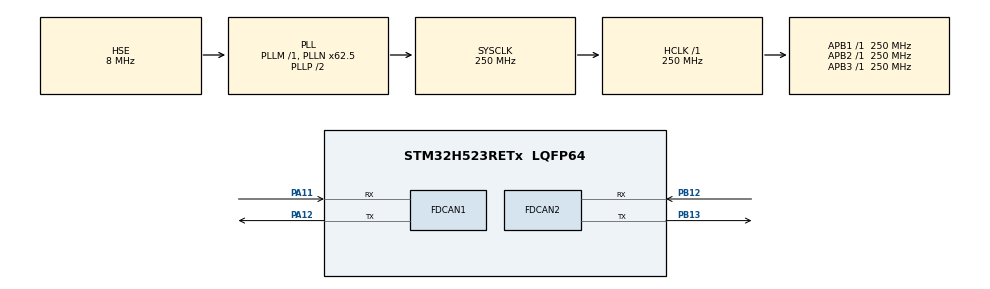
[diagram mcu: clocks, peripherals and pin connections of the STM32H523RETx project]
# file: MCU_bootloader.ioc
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BOOTPATH.BootPathName=LEGACY
BOOTPATH.UserSelectedBootPath=LEGACY
CORTEX_M33_NS.userName=CORTEX_M33
FDCAN1.CalculateBaudRateNominal=250000
FDCAN1.CalculateTimeBitNominal=4000
FDCAN1.CalculateTimeQuantumNominal=1000.0
FDCAN1.DataTimeSeg1=21
FDCAN1.ExtFiltersNbr=1
FDCAN1.NominalPrescaler=8
FDCAN1.NominalTimeSeg1=2
FDCAN1.StdFiltersNbr=1
FDCAN2.CalculateBaudRateNominal=250000
FDCAN2.CalculateTimeBitNominal=4000
FDCAN2.CalculateTimeQuantumNominal=1000.0
FDCAN2.DataTimeSeg1=21
FDCAN2.ExtFiltersNbr=1
FDCAN2.NominalPrescaler=8
FDCAN2.NominalTimeSeg1=2
FDCAN2.StdFiltersNbr=1
Mcu.Family=STM32H5
Mcu.Name=STM32H523RETx
Mcu.Package=LQFP64
NVIC.PriorityGroup=NVIC_PRIORITYGROUP_4
PA11.GPIO_Speed=GPIO_SPEED_FREQ_VERY_HIGH
PA11.Mode=FDCAN_Activate
PA11.Signal=FDCAN1_RX
PA12.GPIO_Speed=GPIO_SPEED_FREQ_VERY_HIGH
PA12.Mode=FDCAN_Activate
PA12.Signal=FDCAN1_TX
PB12.GPIO_Speed=GPIO_SPEED_FREQ_VERY_HIGH
PB12.Mode=FDCAN_Activate
PB12.Signal=FDCAN2_RX
PB13.GPIO_Speed=GPIO_SPEED_FREQ_VERY_HIGH
PB13.Mode=FDCAN_Activate
PB13.Signal=FDCAN2_TX
PH0-OSC_IN(PH0).Mode=HSE-External-Oscillator
PH0-OSC_IN(PH0).Signal=RCC_OSC_IN
PH1-OSC_OUT(PH1).Mode=HSE-External-Oscillator
PH1-OSC_OUT(PH1).Signal=RCC_OSC_OUT
ProjectManager.HeapSize=0x200
ProjectManager.StackSize=0x400
ProjectManager.TargetToolchain=STM32CubeIDE
RCC.ADCFreq_Value=250000000
RCC.AHBFreq_Value=250000000
RCC.APB1Freq_Value=250000000
RCC.APB1TimFreq_Value=250000000
RCC.APB2Freq_Value=250000000
RCC.APB2TimFreq_Value=250000000
RCC.APB3Freq_Value=250000000
RCC.CSI_VALUE=4000000
RCC.CortexFreq_Value=250000000
RCC.EPOD_VALUE=8000000
RCC.HCLKFreq_Value=250000000
RCC.HSE_VALUE=8000000
RCC.HSI48_VALUE=48000000
RCC.HSI_VALUE=64000000
RCC.LSE_VALUE=32768
RCC.LSIRC_VALUE=32000
RCC.PLL1Q=125
RCC.PLL2FRACN=0
RCC.PLL2Source=RCC_PLL2_SOURCE_HSE
RCC.PLL3FRACN=0
RCC.PLL3Source=RCC_PLL3_SOURCE_HSE
RCC.PLLFRACN=4096
RCC.PLLN=62
RCC.PLLSourceVirtual=RCC_PLL1_SOURCE_HSE
RCC.SYSCLKFreq_VALUE=250000000
RCC.SYSCLKSource=RCC_SYSCLKSOURCE_PLLCLK
RCC.USBFreq_Value=48000000
RCC.VCOOutputFreq_Value=500000000
VP_BOOTPATH_VS_BOOTPATH.Mode=BP_Activate
VP_CORTEX_M33_NS_VS_Hclk.Mode=Hclk_Mode
VP_MEMORYMAP_VS_MEMORYMAP.Mode=CurAppReg
VP_PWR_VS_LPOM.Mode=PowerOptimisation
VP_PWR_VS_SECSignals.Mode=Security/Privilege
board=custom

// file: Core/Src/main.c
/* USER CODE BEGIN Header */
/**
  ******************************************************************************
  * @file           : main.c
  * @brief          : Main program body
  ******************************************************************************
  * @attention
  *
  * Copyright (c) 2026 STMicroelectronics.
  * All rights reserved.
  *
  * This software is licensed under terms that can be found in the LICENSE file
  * in the root directory of this software component.
  * If no LICENSE file comes with this software, it is provided AS-IS.
  *
  ******************************************************************************
  */
/* USER CODE END Header */
#include "main.h"

/* USER CODE BEGIN Includes */
#include "boot.h"
/* USER CODE END Includes */

FDCAN_HandleTypeDef hfdcan1;
FDCAN_HandleTypeDef hfdcan2;

void SystemClock_Config(void);
static void MX_GPIO_Init(void);
static void MX_FDCAN1_Init(void);
static void MX_FDCAN2_Init(void);

int main(void)
{

  /* MCU Configuration--------------------------------------------------------*/

  /* Reset of all peripherals, Initializes the Flash interface and the Systick. */
  HAL_Init();

  /* Configure the system clock */
  SystemClock_Config();

  /* Initialize all configured peripherals */
  MX_GPIO_Init();
  MX_FDCAN1_Init();
  MX_FDCAN2_Init();

  /* Infinite loop */
  /* USER CODE BEGIN WHILE */
  BootProcess();
  while (1)
  {
    /* USER CODE END WHILE */

  }
}

void SystemClock_Config(void)
{
  RCC_OscInitTypeDef RCC_OscInitStruct = {0};
  RCC_ClkInitTypeDef RCC_ClkInitStruct = {0};

  /** Configure the main internal regulator output voltage
  */
  __HAL_PWR_VOLTAGESCALING_CONFIG(PWR_REGULATOR_VOLTAGE_SCALE0);

  while(!__HAL_PWR_GET_FLAG(PWR_FLAG_VOSRDY)) {}

  /** Initializes the RCC Oscillators according to the specified parameters
  * in the RCC_OscInitTypeDef structure.
  */
  RCC_OscInitStruct.OscillatorType = RCC_OSCILLATORTYPE_HSE;
  RCC_OscInitStruct.HSEState = RCC_HSE_ON;
  RCC_OscInitStruct.PLL.PLLState = RCC_PLL_ON;
  RCC_OscInitStruct.PLL.PLLSource = RCC_PLL1_SOURCE_HSE;
  RCC_OscInitStruct.PLL.PLLM = 1;
  RCC_OscInitStruct.PLL.PLLN = 62;
  RCC_OscInitStruct.PLL.PLLP = 2;
  RCC_OscInitStruct.PLL.PLLQ = 125;
  RCC_OscInitStruct.PLL.PLLR = 2;
  RCC_OscInitStruct.PLL.PLLRGE = RCC_PLL1_VCIRANGE_3;
  RCC_OscInitStruct.PLL.PLLVCOSEL = RCC_PLL1_VCORANGE_WIDE;
  RCC_OscInitStruct.PLL.PLLFRACN = 4096;
  if (HAL_RCC_OscConfig(&RCC_OscInitStruct) != HAL_OK)
  {
    Error_Handler();
  }

  /** Initializes the CPU, AHB and APB buses clocks
  */
  RCC_ClkInitStruct.ClockType = RCC_CLOCKTYPE_HCLK|RCC_CLOCKTYPE_SYSCLK
                              |RCC_CLOCKTYPE_PCLK1|RCC_CLOCKTYPE_PCLK2
                              |RCC_CLOCKTYPE_PCLK3;
  RCC_ClkInitStruct.SYSCLKSource = RCC_SYSCLKSOURCE_PLLCLK;
  RCC_ClkInitStruct.AHBCLKDivider = RCC_SYSCLK_DIV1;
  RCC_ClkInitStruct.APB1CLKDivider = RCC_HCLK_DIV1;
  RCC_ClkInitStruct.APB2CLKDivider = RCC_HCLK_DIV1;
  RCC_ClkInitStruct.APB3CLKDivider = RCC_HCLK_DIV1;

  if (HAL_RCC_ClockConfig(&RCC_ClkInitStruct, FLASH_LATENCY_5) != HAL_OK)
  {
    Error_Handler();
  }

  /** Configure the programming delay
  */
  __HAL_FLASH_SET_PROGRAM_DELAY(FLASH_PROGRAMMING_DELAY_2);
}

static void MX_FDCAN1_Init(void)
{

  hfdcan1.Instance = FDCAN1;
  hfdcan1.Init.ClockDivider = FDCAN_CLOCK_DIV1;
  hfdcan1.Init.FrameFormat = FDCAN_FRAME_CLASSIC;
  hfdcan1.Init.Mode = FDCAN_MODE_NORMAL;
  hfdcan1.Init.AutoRetransmission = DISABLE;
  hfdcan1.Init.TransmitPause = DISABLE;
  hfdcan1.Init.ProtocolException = DISABLE;
  hfdcan1.Init.NominalPrescaler = 8;
  hfdcan1.Init.NominalSyncJumpWidth = 1;
  hfdcan1.Init.NominalTimeSeg1 = 2;
  hfdcan1.Init.NominalTimeSeg2 = 1;
  hfdcan1.Init.DataPrescaler = 1;
  hfdcan1.Init.DataSyncJumpWidth = 1;
  hfdcan1.Init.DataTimeSeg1 = 21;
  hfdcan1.Init.DataTimeSeg2 = 1;
  hfdcan1.Init.StdFiltersNbr = 1;
  hfdcan1.Init.ExtFiltersNbr = 1;
  hfdcan1.Init.TxFifoQueueMode = FDCAN_TX_FIFO_OPERATION;
  if (HAL_FDCAN_Init(&hfdcan1) != HAL_OK)
  {
    Error_Handler();
  }

}

static void MX_FDCAN2_Init(void)
{

  hfdcan2.Instance = FDCAN2;
  hfdcan2.Init.ClockDivider = FDCAN_CLOCK_DIV1;
  hfdcan2.Init.FrameFormat = FDCAN_FRAME_CLASSIC;
  hfdcan2.Init.Mode = FDCAN_MODE_NORMAL;
  hfdcan2.Init.AutoRetransmission = DISABLE;
  hfdcan2.Init.TransmitPause = DISABLE;
  hfdcan2.Init.ProtocolException = DISABLE;
  hfdcan2.Init.NominalPrescaler = 8;
  hfdcan2.Init.NominalSyncJumpWidth = 1;
  hfdcan2.Init.NominalTimeSeg1 = 2;
  hfdcan2.Init.NominalTimeSeg2 = 1;
  hfdcan2.Init.DataPrescaler = 1;
  hfdcan2.Init.DataSyncJumpWidth = 1;
  hfdcan2.Init.DataTimeSeg1 = 21;
  hfdcan2.Init.DataTimeSeg2 = 1;
  hfdcan2.Init.StdFiltersNbr = 1;
  hfdcan2.Init.ExtFiltersNbr = 1;
  hfdcan2.Init.TxFifoQueueMode = FDCAN_TX_FIFO_OPERATION;
  if (HAL_FDCAN_Init(&hfdcan2) != HAL_OK)
  {
    Error_Handler();
  }

}

static void MX_GPIO_Init(void)
{

  /* GPIO Ports Clock Enable */
  __HAL_RCC_GPIOH_CLK_ENABLE();
  __HAL_RCC_GPIOB_CLK_ENABLE();
  __HAL_RCC_GPIOA_CLK_ENABLE();

}

void Error_Handler(void)
{
  __disable_irq();
  while (1)
  {
  }
}
